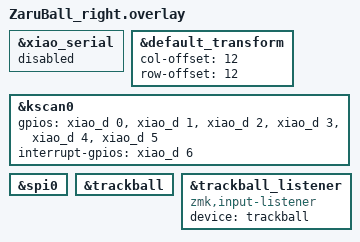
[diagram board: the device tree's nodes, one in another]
#include "ZaruBall.dtsi"
#include <dt-bindings/zmk/input_transform.h>

&xiao_serial { status = "disabled"; };

// matrix transformでのピン数オフセット
&default_transform { // Offset of 7 because the left side has 2 columns
    col-offset = <12>;
    row-offset = <12>;
};

&kscan0 {
    gpios
        = <&xiao_d 0 GPIO_ACTIVE_HIGH>//M1
        , <&xiao_d 1 GPIO_ACTIVE_HIGH>//M2
        , <&xiao_d 2 GPIO_ACTIVE_HIGH>//M3
        , <&xiao_d 3 GPIO_ACTIVE_HIGH>//M4
        , <&xiao_d 4 GPIO_ACTIVE_HIGH>//M5
        , <&xiao_d 5 GPIO_ACTIVE_HIGH>//M6
        ;
    interrupt-gpios = <&xiao_d 6 (GPIO_ACTIVE_HIGH | GPIO_PULL_DOWN)>;//IGPIO
};

&spi0 {
    status = "okay";
};

&trackball {
    status = "okay";
};

// pmw-3610
&trackball_listener {
    status = "okay";
    compatible = "zmk,input-listener";
    device = <&trackball>;
};
